VERSION "HIPBNYYYYYYYYYYYYYYYYYYYYYYYYYYYYYYYYYYYYY/4/%%%/4/'%**4YYY///"

NS_ :

BS_:

BU_: DBG VCU BMS MCM DCU DAQ S2C

BO_ 1200 DAQ_LF_Tire_Temp_Ch1_4: 8 DAQ
 SG_ LF_Temperature_4 : 48|16@0+ (0.001,-100) [0|100] "C" DAQ
 SG_ LF_Temperature_3 : 32|16@0+ (0.001,-100) [0|100] "C" DAQ
 SG_ LF_Temperature_2 : 16|16@0+ (0.001,-100) [0|100] "C" DAQ
 SG_ LF_Temperature_1 : 0|16@0+ (0.001,-100) [0|100] "C" DAQ

BO_ 1201 DAQ_LF_Tire_Temp_Ch5_8: 8 DAQ
 SG_ LF_Temperature_8 : 48|16@0+ (0.001,-100) [0|100] "C" DAQ
 SG_ LF_Temperature_7 : 32|16@0+ (0.001,-100) [0|100] "C" DAQ
 SG_ LF_Temperature_6 : 16|16@0+ (0.001,-100) [0|100] "C" DAQ
 SG_ LF_Temperature_5 : 0|16@0+ (0.001,-100) [0|100] "C" DAQ

BO_ 1202 DAQ_LF_Tire_Temp_Ch9_12: 8 DAQ
 SG_ LF_Temperature_12 : 48|16@0+ (0.001,-100) [0|100] "C" DAQ
 SG_ LF_Temperature_11 : 32|16@0+ (0.001,-100) [0|100] "C" DAQ
 SG_ LF_Temperature_10 : 16|16@0+ (0.001,-100) [0|100] "C" DAQ
 SG_ LF_Temperature_9 : 0|16@0+ (0.001,-100) [0|100] "C" DAQ

BO_ 1203 DAQ_LF_Tire_Temp_Ch13_16: 8 DAQ
 SG_ LF_Temperature_16 : 48|16@0+ (0.001,-100) [0|100] "C" DAQ
 SG_ LF_Temperature_15 : 32|16@0+ (0.001,-100) [0|100] "C" DAQ
 SG_ LF_Temperature_14 : 16|16@0+ (0.001,-100) [0|100] "C" DAQ
 SG_ LF_Temperature_13 : 0|16@0+ (0.001,-100) [0|100] "C" DAQ

BO_ 1204 DAQ_RF_Tire_Temp_Ch1_4: 8 DAQ
 SG_ RF_Temperature_4 : 48|16@0+ (0.001,-100) [0|100] "C" DAQ
 SG_ RF_Temperature_3 : 32|16@0+ (0.001,-100) [0|100] "C" DAQ
 SG_ RF_Temperature_2 : 16|16@0+ (0.001,-100) [0|100] "C" DAQ
 SG_ RF_Temperature_1 : 0|16@0+ (0.001,-100) [0|100] "C" DAQ

BO_ 1205 DAQ_RF_Tire_Temp_Ch5_8: 8 DAQ
 SG_ RF_Temperature_8 : 48|16@0+ (0.001,-100) [0|100] "C" DAQ
 SG_ RF_Temperature_7 : 32|16@0+ (0.001,-100) [0|100] "C" DAQ
 SG_ RF_Temperature_6 : 16|16@0+ (0.001,-100) [0|100] "C" DAQ
 SG_ RF_Temperature_5 : 0|16@0+ (0.001,-100) [0|100] "C" DAQ

BO_ 1206 DAQ_RF_Tire_Temp_Ch9_12: 8 DAQ
 SG_ RF_Temperature_12 : 48|16@0+ (0.001,-100) [0|100] "C" DAQ
 SG_ RF_Temperature_11 : 32|16@0+ (0.001,-100) [0|100] "C" DAQ
 SG_ RF_Temperature_10 : 16|16@0+ (0.001,-100) [0|100] "C" DAQ
 SG_ RF_Temperature_9 : 0|16@0+ (0.001,-100) [0|100] "C" DAQ

BO_ 1207 DAQ_RF_Tire_Temp_Ch13_16: 8 DAQ
 SG_ RF_Temperature_16 : 48|16@0+ (0.001,-100) [0|100] "C" DAQ
 SG_ RF_Temperature_15 : 32|16@0+ (0.001,-100) [0|100] "C" DAQ
 SG_ RF_Temperature_14 : 16|16@0+ (0.001,-100) [0|100] "C" DAQ
 SG_ RF_Temperature_13 : 0|16@0+ (0.001,-100) [0|100] "C" DAQ

BO_ 1208 DAQ_LR_Tire_Temp_Ch1_4: 8 DAQ
 SG_ LR_Temperature_4 : 48|16@0+ (0.001,-100) [0|100] "C" DAQ
 SG_ LR_Temperature_3 : 32|16@0+ (0.001,-100) [0|100] "C" DAQ
 SG_ LR_Temperature_2 : 16|16@0+ (0.001,-100) [0|100] "C" DAQ
 SG_ LR_Temperature_1 : 0|16@0+ (0.001,-100) [0|100] "C" DAQ

BO_ 1209 DAQ_LR_Tire_Temp_Ch5_8: 8 DAQ
 SG_ LR_Temperature_8 : 48|16@0+ (0.001,-100) [0|100] "C" DAQ
 SG_ LR_Temperature_7 : 32|16@0+ (0.001,-100) [0|100] "C" DAQ
 SG_ LR_Temperature_6 : 16|16@0+ (0.001,-100) [0|100] "C" DAQ
 SG_ LR_Temperature_5 : 0|16@0+ (0.001,-100) [0|100] "C" DAQ

BO_ 1210 DAQ_LR_Tire_Temp_Ch9_12: 8 DAQ
 SG_ LR_Temperature_12 : 48|16@0+ (0.001,-100) [0|100] "C" DAQ
 SG_ LR_Temperature_11 : 32|16@0+ (0.001,-100) [0|100] "C" DAQ
 SG_ LR_Temperature_10 : 16|16@0+ (0.001,-100) [0|100] "C" DAQ
 SG_ LR_Temperature_9 : 0|16@0+ (0.001,-100) [0|100] "C" DAQ

BO_ 1211 DAQ_LR_Tire_Temp_Ch13_16: 8 DAQ
 SG_ LR_Temperature_16 : 48|16@0+ (0.001,-100) [0|100] "C" DAQ
 SG_ LR_Temperature_15 : 32|16@0+ (0.001,-100) [0|100] "C" DAQ
 SG_ LR_Temperature_14 : 16|16@0+ (0.001,-100) [0|100] "C" DAQ
 SG_ LR_Temperature_13 : 0|16@0+ (0.001,-100) [0|100] "C" DAQ

BO_ 1212 DAQ_RR_Tire_Temp_Ch1_4: 8 DAQ
 SG_ RR_Temperature_4 : 48|16@0+ (0.001,-100) [0|100] "C" DAQ
 SG_ RR_Temperature_3 : 32|16@0+ (0.001,-100) [0|100] "C" DAQ
 SG_ RR_Temperature_2 : 16|16@0+ (0.001,-100) [0|100] "C" DAQ
 SG_ RR_Temperature_1 : 0|16@0+ (0.001,-100) [0|100] "C" DAQ

BO_ 1213 DAQ_RR_Tire_Temp_Ch5_8: 8 DAQ
 SG_ RR_Temperature_8 : 48|16@0+ (0.001,-100) [0|100] "C" DAQ
 SG_ RR_Temperature_7 : 32|16@0+ (0.001,-100) [0|100] "C" DAQ
 SG_ RR_Temperature_6 : 16|16@0+ (0.001,-100) [0|100] "C" DAQ
 SG_ RR_Temperature_5 : 0|16@0+ (0.001,-100) [0|100] "C" DAQ
BO_ 1025 GPS_Speed: 8 Aceinna
 SG_ Speed : 0|16@1- (0.001,0) [-1000|1000] "kph" Vector__XXX

BO_ 1214 DAQ_RR_Tire_Temp_Ch9_12: 8 DAQ
 SG_ RR_Temperature_12 : 48|16@0+ (0.001,-100) [0|100] "C" DAQ
 SG_ RR_Temperature_11 : 32|16@0+ (0.001,-100) [0|100] "C" DAQ
 SG_ RR_Temperature_10 : 16|16@0+ (0.001,-100) [0|100] "C" DAQ
 SG_ RR_Temperature_9 : 0|16@0+ (0.001,-100) [0|100] "C" DAQ

BO_ 1215 DAQ_RR_Tire_Temp_Ch13_16: 8 DAQ
 SG_ RR_Temperature_16 : 48|16@0+ (0.001,-100) [0|100] "C" DAQ
 SG_ RR_Temperature_15 : 32|16@0+ (0.001,-100) [0|100] "C" DAQ
 SG_ RR_Temperature_14 : 16|16@0+ (0.001,-100) [0|100] "C" DAQ
 SG_ RR_Temperature_13 : 0|16@0+ (0.001,-100) [0|100] "C" DAQ

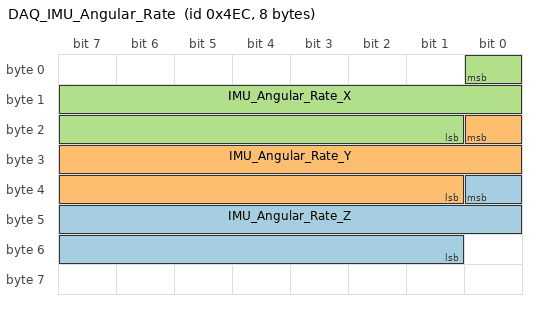
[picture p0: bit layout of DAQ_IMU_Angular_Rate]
BO_ 1260 DAQ_IMU_Angular_Rate: 8 DAQ
 SG_ IMU_Angular_Rate_Z : 32|16@0- (0.001,0) [-250|250] "dps" DAQ
 SG_ IMU_Angular_Rate_Y : 16|16@0- (0.001,0) [-250|250] "dps" DAQ
 SG_ IMU_Angular_Rate_X : 0|16@0- (0.001,0) [-250|250] "dps" DAQ

BO_ 1261 DAQ_IMU_Acceleration: 8 DAQ
 SG_ IMU_Temperature : 48|16@0- (0.01,0) [-10|10] "C" DAQ
 SG_ IMU_Acceleration_Z : 32|16@0- (0.0001,0) [-10|10] "g" DAQ
 SG_ IMU_Acceleration_Y : 16|16@0- (0.0001,0) [-10|10] "g" DAQ
 SG_ IMU_Acceleration_X : 0|16@0- (0.0001,0) [-10|10] "g" DAQ
